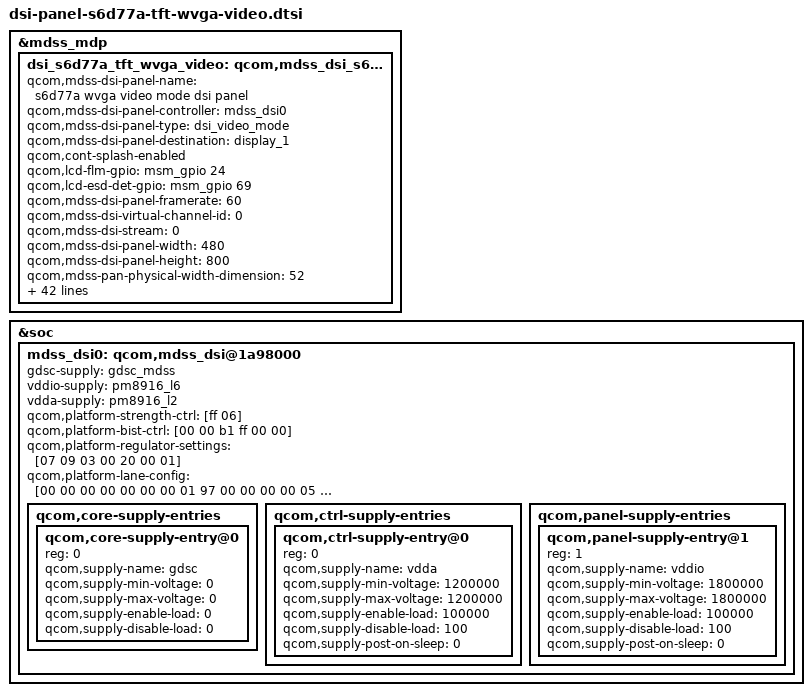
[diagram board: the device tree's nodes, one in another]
/* Copyright (c) 2013-14, Samsung Electronics Corporation. All rights reserved.
 *
 * This program is free software; you can redistribute it and/or modify
 * it under the terms of the GNU General Public License version 2 and
 * only version 2 as published by the Free Software Foundation.
 *
 * This program is distributed in the hope that it will be useful,
 * but WITHOUT ANY WARRANTY; without even the implied warranty of
 * MERCHANTABILITY or FITNESS FOR A PARTICULAR PURPOSE.  See the
 * GNU General Public License for more details.
 */

/*---------------------------------------------------------------------------
 * This file is autogenerated file using gcdb parser. Please do not edit it.
 * Update input XML file to add a new entry or update variable in this file
 * VERSION = "1.0"
 *---------------------------------------------------------------------------

 */
&mdss_mdp {
	dsi_s6d77a_tft_wvga_video: qcom,mdss_dsi_s6d77a_tft_wvga_video {
		qcom,mdss-dsi-panel-name = "s6d77a wvga video mode dsi panel";
		qcom,mdss-dsi-panel-controller = <&mdss_dsi0>;
		qcom,mdss-dsi-panel-type = "dsi_video_mode";
		qcom,mdss-dsi-panel-destination = "display_1";
		qcom,cont-splash-enabled;
		qcom,lcd-flm-gpio = <&msm_gpio 24 0>;
		qcom,lcd-esd-det-gpio = <&msm_gpio 69 0>;
		qcom,mdss-dsi-panel-framerate = <60>;
		qcom,mdss-dsi-virtual-channel-id = <0>;
		qcom,mdss-dsi-stream = <0>;
		qcom,mdss-dsi-panel-width = <480>;
		qcom,mdss-dsi-panel-height = <800>;
		qcom,mdss-pan-physical-width-dimension = <52>; /* <Width> real size of panel in mm */
		qcom,mdss-pan-physical-height-dimension = <87>; /*<Height> real size of panel in mm */
		qcom,mdss-dsi-lp11-init;
		qcom,mdss-dsi-init-delay-us = <100>;
		qcom,mdss-dsi-h-front-porch = <74>;
		qcom,mdss-dsi-h-back-porch = <88>;
		qcom,mdss-dsi-h-pulse-width = <26>;
		qcom,mdss-dsi-h-sync-skew = <0>;
		qcom,mdss-dsi-v-back-porch = <12>;
		qcom,mdss-dsi-v-front-porch = <16>;
		qcom,mdss-dsi-v-pulse-width = <4>;
		qcom,mdss-dsi-h-left-border = <0>;
		qcom,mdss-dsi-h-right-border = <0>;
		qcom,mdss-dsi-v-top-border = <0>;
		qcom,mdss-dsi-v-bottom-border = <0>;
		qcom,mdss-dsi-bpp = <24>;
		qcom,mdss-dsi-color-order = <0>;
		qcom,mdss-dsi-underflow-color = <0xff>;
		qcom,mdss-dsi-border-color = <0>;
		qcom,mdss-dsi-dma-trigger = "trigger_sw";
		qcom,mdss-dsi-mdp-trigger = "none";
		qcom,mdss-dsi-bl-min-level = <0>;
		qcom,mdss-dsi-bl-max-level = <100>;
		qcom,mdss-dsi-lane-0-state;
		qcom,mdss-dsi-lane-1-state;
		qcom,mdss-dsi-bllp-eof-power-mode;
		qcom,mdss-dsi-bllp-power-mode;
		qcom,mdss-dsi-traffic-mode = "burst_mode";
		qcom,mdss-force-clk-lane-hs = <0>;
		qcom,mdss-dsi-reset-sequence = <1 20>, <0 1>, <1 20>;
		qcom,mdss-dsi-h-sync-pulse = <0>;
		qcom,mdss-dsi-panel-timings = [86 1E 14 00 42 46 18 20 16 03 04 00];  //[76 18 10 00 3c 40 14 1c 12 03 04 00];
		qcom,mdss-dsi-t-clk-pre = <0x1B>;//1B
		qcom,mdss-dsi-t-clk-post = <0x04>;
		qcom,mdss-dsi-on-command = [

								/* Sleep out */
					05 01 00 00 78 00 02
					11 00
					/*power setting*/
					39 01 00 00 00 00 03
					F0 5A 5A

					39 01 00 00 00 00 03
					F1 5A 5A

					39 01 00 00 00 00 03
					FC A5 A5

					39 01 00 00 00 00 02
					B3 01

					39 01 00 00 00 00 02
					B5 10

					39 01 00 00 00 00 04
					BC 00 29 51

					39 01 00 00 00 00 03
					E3 24 2C



					39 01 00 00 00 00 09
					F2 11 04 08 10 10 72 4A 0A

					39 01 00 00 00 00 06
					F3 91 00 00 00 10

					39 01 00 00 00 00 2C
					F4 01 02 23 24 25 25 26 26 29 29
					2C 2B 2C 07 08 05 04 04 01 01
					22 0A 17 0F 11 23 0D 0A 0B 02
					19 13 1E 1F 23 20 05 16 1A 16
					1E 24 1E

					39 01 00 00 00 00 1D
					F5 14 14 B9 21 35 55 36 0A 00 39
					00 00 0B 4B C4 CB 4B 12 12 1A
					00 10 E0 E2 0E 34 34 03

					39 01 00 00 0A 00 12
					FE 00 02 01 39 60 40 21 00 4B 00
					80 00 F0 00 00 00 06

					/* Initializing */
					39 01 00 00 00 00 0B
					EE 40 A0 40 A0 00 00 00 00 00 00

					39 01 00 00 00 00 15
					EF 23 01 00 00 2A 49 08 27 21 40
					10 24 02 21 21 03 03 40 00 08

					39 01 00 00 00 00 1F
					F7 02 1B 1A 00 01 0E 0E 0A 0A 0F
					0F 0B 0B 05 07 02 1B 1A 00 01
					0C 0C 08 08 0D 0D 09 09 04 06

					39 01 00 00 00 00 07
					F6 63 25 15 00 00 20

					39 01 00 00 00 00 02
					36 10

					/* Gamma Setting */
					39 01 00 00 00 00 12
					FA 0C 36 0B 10 07 0C 10 10 14 1D
					1F 1E 20 21 22 25 2F

					05 01 00 00 78 00 02
					21 00

					39 01 00 00 00 00 12
					FB 0C 36 0B 10 07 0C 10 0E 0E 15
					1B 1E 20 1F 20 25 2F

					/* Display on */
					05 01 00 00 78 00 02
					29 00
					];

		samsung,panel-manufacture-id-read-cmds = [06 01 00 00 00 00 01 da 01
							06 01 00 00 00 00 01 db 01
							06 01 00 00 00 00 01 dc 01];

		qcom,mdss-dsi-on-command-state = "dsi_lp_mode";

		qcom,mdss-dsi-off-command-state = "dsi_hs_mode";
		qcom,mdss-dsi-off-command = [39 01 00 60  00 02 28 00
					39 01 00 00 82 00 02 10 00];
	};
};
&soc {
	mdss_dsi0: qcom,mdss_dsi@1a98000 {
		gdsc-supply = <&gdsc_mdss>;
		vddio-supply = <&pm8916_l6>;
		vdda-supply = <&pm8916_l2>;
		qcom,platform-strength-ctrl = [ff 06];
		qcom,platform-bist-ctrl = [00 00 b1 ff 00 00];
		qcom,platform-regulator-settings = [07 09 03 00 20 00 01];
		qcom,platform-lane-config = [00 00 00 00 00 00 00 01 97
			00 00 00 00 05 00 00 01 97
			00 00 00 00 0a 00 00 01 97
			00 00 00 00 0f 00 00 01 97
			00 c0 00 00 00 00 00 01 bb];
		qcom,core-supply-entries {
			#address-cells = <1>;
			#size-cells = <0>;

			qcom,core-supply-entry@0 {
				reg = <0>;
				qcom,supply-name = "gdsc";
				qcom,supply-min-voltage = <0>;
				qcom,supply-max-voltage = <0>;
				qcom,supply-enable-load = <0>;
				qcom,supply-disable-load = <0>;
			};
		};
		qcom,ctrl-supply-entries {
			#address-cells = <1>;
			#size-cells = <0>;

			qcom,ctrl-supply-entry@0 {
				reg = <0>;
				qcom,supply-name = "vdda";
				qcom,supply-min-voltage = <1200000>;
				qcom,supply-max-voltage = <1200000>;
				qcom,supply-enable-load = <100000>;
				qcom,supply-disable-load = <100>;
				qcom,supply-post-on-sleep = <0>;
			};
		};
		qcom,panel-supply-entries {
			#address-cells = <1>;
			#size-cells = <0>;

			qcom,panel-supply-entry@1 {
				reg = <1>;
				qcom,supply-name = "vddio";
				qcom,supply-min-voltage = <1800000>;
				qcom,supply-max-voltage = <1800000>;
				qcom,supply-enable-load = <100000>;
				qcom,supply-disable-load = <100>;
				qcom,supply-post-on-sleep = <0>;
			};
		};
	};
};

